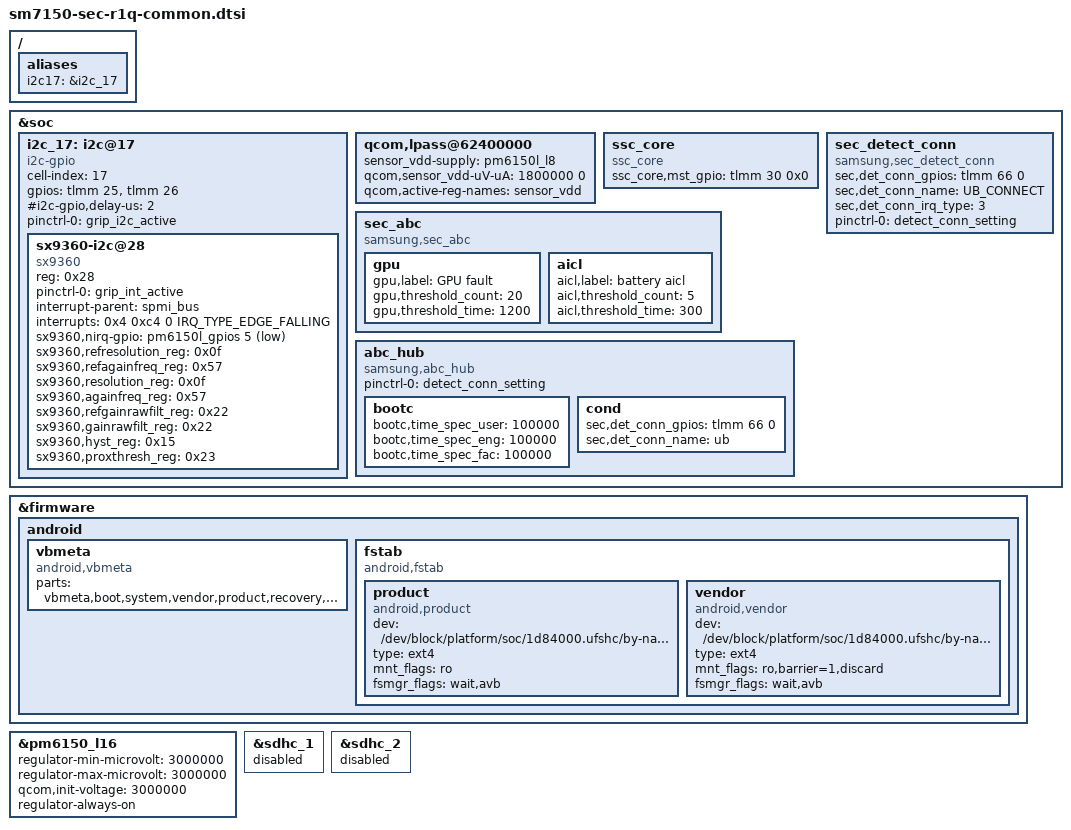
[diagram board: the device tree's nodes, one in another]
/* Copyright (c) 2018, The Linux Foundation. All rights reserved.
 *
 * This program is free software; you can redistribute it and/or modify
 * it under the terms of the GNU General Public License version 2 and
 * only version 2 as published by the Free Software Foundation.
 *
 * This program is distributed in the hope that it will be useful,
 * but WITHOUT ANY WARRANTY; without even the implied warranty of
 * MERCHANTABILITY or FITNESS FOR A PARTICULAR PURPOSE.  See the
 * GNU General Public License for more details.
 */

#include "sm7150-sec-r1q-audio.dtsi"
#include "sm7150-sec-r1q-input-common.dtsi"
#include "sm7150-sec-r1q-mst-r00.dtsi"

/{
	aliases {
		i2c17 = &i2c_17;
	};
};

&soc {
	i2c_17: i2c@17 { /* SW I2C */
		status = "ok";

		cell-index = <17>;
		compatible = "i2c-gpio";
		gpios = <&tlmm 25 0 /* sda */
			 &tlmm 26 0 /* scl */
		>;
		#i2c-gpio,delay-us = <2>;
		#address-cells = <1>;
		#size-cells = <0>;
		pinctrl-names = "default";
		pinctrl-0 = <&grip_i2c_active>;

		sx9360-i2c@28 {
			compatible = "sx9360";
			reg = <0x28>;
			pinctrl-names = "default";
			pinctrl-0 = <&grip_int_active>;

			interrupt-parent = <&spmi_bus>;
			interrupts = <0x4 0xc4 0 IRQ_TYPE_EDGE_FALLING>;

			sx9360,nirq-gpio = <&pm6150l_gpios 5 GPIO_ACTIVE_LOW>;
			sx9360,refresolution_reg = <0x0f>; /* same as resolution_reg */
			sx9360,refagainfreq_reg = <0x57>; /* same as againfreq_reg */
			sx9360,resolution_reg = <0x0f>; /* resolution : 1024 */
        		sx9360,againfreq_reg = <0x57>; /* freq : 71.43 kHz, again : +/-7.5 pF */
        		sx9360,refgainrawfilt_reg = <0x22>; /* same as gainrawfilt_reg */
        		sx9360,gainrawfilt_reg = <0x22>; /* rawfilter : 1-1/4, gain : x8 */
        		sx9360,hyst_reg = <0x15>; /* hysteresis : +/-6 %, debouncer : 2 samples */
        		sx9360,proxthresh_reg = <0x23>; /* threshhold : 612 */
		};
	};

	/* Sensor */
       	qcom,lpass@62400000 {
		sensor_vdd-supply = <&pm6150l_l8>;
		qcom,sensor_vdd-uV-uA = <1800000 0>;
		qcom,active-reg-names = "sensor_vdd";
       	};

	ssc_core {
		status = "okay";
		compatible = "ssc_core";
		ssc_core,mst_gpio = <&tlmm 30 0x0>;
	};

	sec_detect_conn {
		compatible = "samsung,sec_detect_conn";
		sec,det_conn_gpios = <&tlmm 66 0>; /* UB_CON_DETECT */

		sec,det_conn_name = "UB_CONNECT";

		sec,det_conn_irq_type = <3>; /* UB_CON_DETECT FALLING, RIGING EDGE*/

		pinctrl-names = "det_ap_connect";
		pinctrl-0 = <&detect_conn_setting>;
	};
	
	sec_abc {
				compatible = "samsung,sec_abc";
				status = "okay";

				gpu {
					gpu,label="GPU fault";
					gpu,threshold_count=<20>;
					gpu,threshold_time=<1200>;
				};
				aicl {
					aicl,label="battery aicl";
					aicl,threshold_count=<5>;
					aicl,threshold_time=<300>;
				};
			};

	abc_hub {
		compatible = "samsung,abc_hub";
		status = "okay";

		pinctrl-names = "det_ap_connect";
		pinctrl-0 = <&detect_conn_setting>;

		bootc {
			bootc,time_spec_user = <100000>; /* user binary user build */
			bootc,time_spec_eng = <100000>; /* user binary eng build */
			bootc,time_spec_fac = <100000>; /* factory binary */
		};

		cond {
			sec,det_conn_gpios = <&tlmm 66 0>; /* UB_CONNECT */
			sec,det_conn_name = "ub";
		};
	};
};

&firmware {
	android {
		vbmeta {
			compatible = "android,vbmeta";
			parts = "vbmeta,boot,system,vendor,product,recovery,dtbo,abl,xbl,tz,hyp";
		};
		fstab {
			compatible = "android,fstab";
			product {
				compatible = "android,product";
				/* dev = "/dev/block/bootdevice/by-name/product"; */
				dev = "/dev/block/platform/soc/1d84000.ufshc/by-name/product";
				type = "ext4";
				mnt_flags = "ro";
				fsmgr_flags = "wait,avb";
			};
			vendor {
				compatible = "android,vendor";
				dev = "/dev/block/platform/soc/1d84000.ufshc/by-name/vendor";
				type = "ext4";
				mnt_flags = "ro,barrier=1,discard";
				fsmgr_flags = "wait,avb";
			};
		};
	};
};

/* Grip Sensor */
&pm6150_l16 {
	regulator-min-microvolt = <3000000>;
	regulator-max-microvolt = <3000000>;
	qcom,init-voltage = <3000000>;
	regulator-always-on;
};


/* not use eMMC */
&sdhc_1 {
	status = "disabled";
};
/* not use SDcard */
&sdhc_2 {
	status = "disabled";
};


